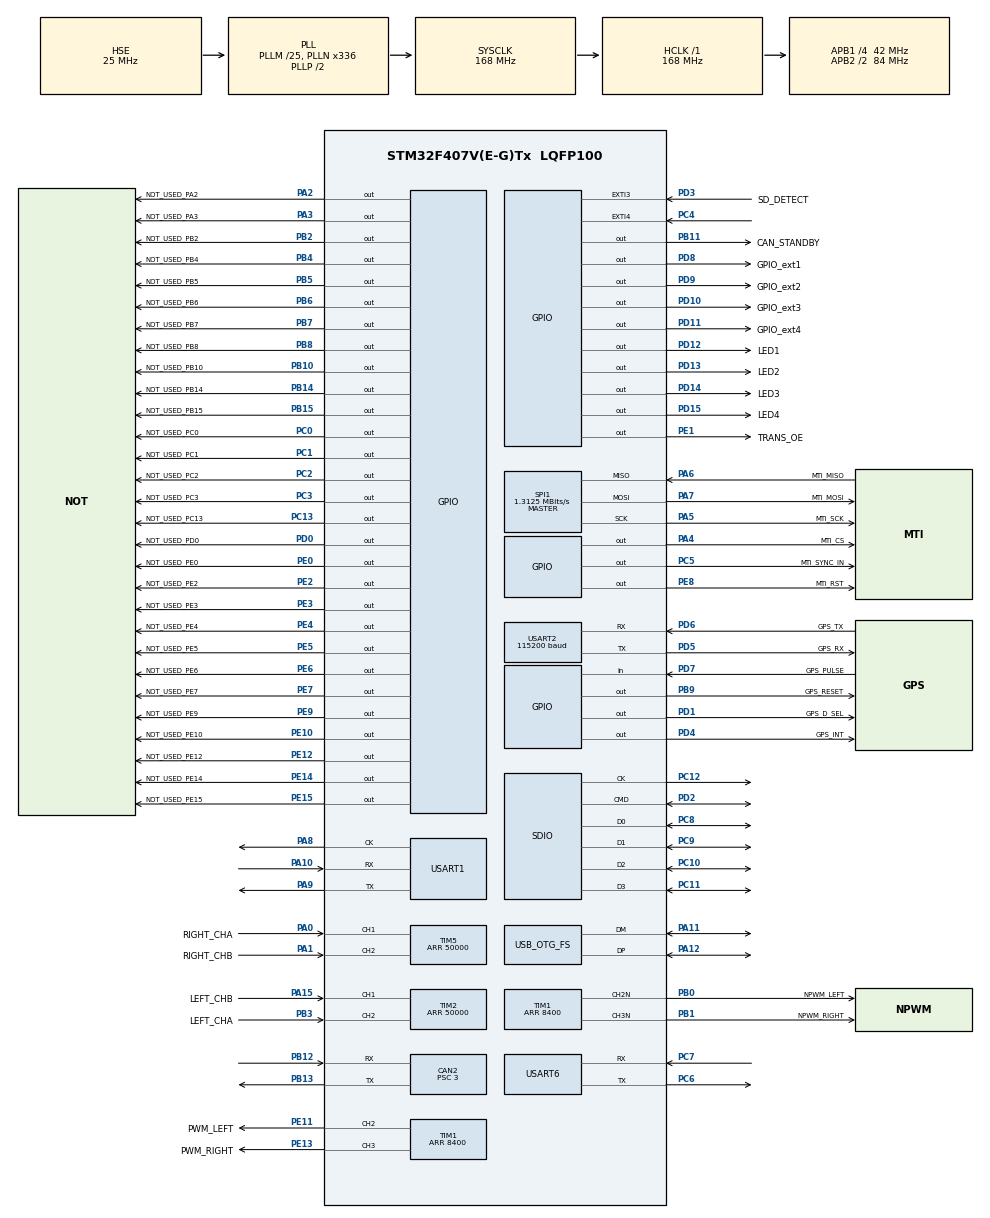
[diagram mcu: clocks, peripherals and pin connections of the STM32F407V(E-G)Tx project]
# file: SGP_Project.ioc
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CAN2.BS1=CAN_BS1_13TQ
CAN2.BS2=CAN_BS2_2TQ
CAN2.CalculateTimeBit=1142
CAN2.CalculateTimeQuantum=71.42857142857143
CAN2.Prescaler=3
Mcu.Family=STM32F4
Mcu.Name=STM32F407V(E-G)Tx
Mcu.Package=LQFP100
NVIC.CAN2_RX0_IRQn=true\:1\:0\:true\:true\:true\:5\:true
NVIC.CAN2_RX1_IRQn=true\:1\:0\:true\:true\:true\:6\:true
NVIC.CAN2_TX_IRQn=true\:0\:0\:false\:false\:true\:true
NVIC.EXTI3_IRQn=true\:1\:0\:true\:true\:true\:1\:true
NVIC.EXTI4_IRQn=true\:0\:0\:false\:true\:true\:10\:true
NVIC.OTG_FS_IRQn=true\:1\:0\:true\:true\:true\:7\:true
NVIC.PriorityGroup=NVIC_PRIORITYGROUP_4
NVIC.TIM3_IRQn=true\:3\:0\:true\:true\:true\:2\:true
NVIC.TIM4_IRQn=true\:4\:0\:true\:true\:true\:3\:true
NVIC.TIM6_DAC_IRQn=true\:2\:0\:true\:true\:true\:4\:true
NVIC.USART2_IRQn=true\:1\:0\:true\:true\:true\:8\:true
NVIC.USART6_IRQn=true\:1\:0\:true\:true\:true\:9\:true
PA0-WKUP.GPIO_Label=RIGHT_CHA
PA0-WKUP.Signal=S_TIM5_CH1
PA1.GPIO_Label=RIGHT_CHB
PA1.Signal=S_TIM5_CH2
PA10.GPIO_Speed=GPIO_SPEED_FREQ_MEDIUM
PA10.Mode=Synchronous
PA10.Signal=USART1_RX
PA11.GPIO_Speed=GPIO_SPEED_FREQ_HIGH
PA11.Mode=Device_Only
PA11.Signal=USB_OTG_FS_DM
PA12.GPIO_Speed=GPIO_SPEED_FREQ_HIGH
PA12.Mode=Device_Only
PA12.Signal=USB_OTG_FS_DP
PA13.Mode=Serial_Wire
PA13.Signal=SYS_JTMS-SWDIO
PA14.Mode=Serial_Wire
PA14.Signal=SYS_JTCK-SWCLK
PA15.GPIO_Label=LEFT_CHB
PA15.Signal=S_TIM2_CH1_ETR
PA2.GPIO_Label=NOT_USED_PA2
PA2.GPIO_PuPd=GPIO_PULLDOWN
PA2.Signal=GPIO_Output
PA3.GPIO_Label=NOT_USED_PA3
PA3.GPIO_PuPd=GPIO_PULLDOWN
PA3.Signal=GPIO_Output
PA4.GPIO_Label=MTi_CS
PA4.GPIO_PuPd=GPIO_PULLDOWN
PA4.Signal=GPIO_Output
PA5.GPIO_Label=MTi_SCK
PA5.Mode=Full_Duplex_Master
PA5.Signal=SPI1_SCK
PA6.GPIO_Label=MTi_MISO
PA6.Mode=Full_Duplex_Master
PA6.Signal=SPI1_MISO
PA7.GPIO_Label=MTi_MOSI
PA7.Mode=Full_Duplex_Master
PA7.Signal=SPI1_MOSI
PA8.GPIO_Speed=GPIO_SPEED_FREQ_MEDIUM
PA8.Mode=Synchronous
PA8.Signal=USART1_CK
PA9.GPIO_Speed=GPIO_SPEED_FREQ_MEDIUM
PA9.Mode=Synchronous
PA9.Signal=USART1_TX
PB0.GPIO_Label=NPWM_LEFT
PB0.Mode=PWM Generation2 CH2 CH2N
PB0.Signal=TIM1_CH2N
PB1.GPIO_Label=NPWM_RIGHT
PB1.Mode=PWM Generation3 CH3 CH3N
PB1.Signal=TIM1_CH3N
PB10.GPIO_Label=NOT_USED_PB10
PB10.GPIO_PuPd=GPIO_PULLDOWN
PB10.Signal=GPIO_Output
PB11.GPIO_Label=CAN_STANDBY
PB11.GPIO_PuPd=GPIO_PULLDOWN
PB11.Signal=GPIO_Output
PB12.GPIO_PuPd=GPIO_PULLUP
PB12.GPIO_Speed=GPIO_SPEED_FREQ_VERY_HIGH
PB12.Mode=Slave
PB12.Signal=CAN2_RX
PB13.GPIO_PuPd=GPIO_PULLUP
PB13.GPIO_Speed=GPIO_SPEED_FREQ_VERY_HIGH
PB13.Mode=Slave
PB13.Signal=CAN2_TX
PB14.GPIO_Label=NOT_USED_PB14
PB14.GPIO_PuPd=GPIO_PULLDOWN
PB14.Signal=GPIO_Output
PB15.GPIO_Label=NOT_USED_PB15
PB15.GPIO_PuPd=GPIO_PULLDOWN
PB15.Signal=GPIO_Output
PB2.GPIO_Label=NOT_USED_PB2
PB2.GPIO_PuPd=GPIO_PULLDOWN
PB2.Signal=GPIO_Output
PB3.GPIO_Label=LEFT_CHA
PB3.Signal=S_TIM2_CH2
PB4.GPIO_Label=NOT_USED_PB4
PB4.GPIO_PuPd=GPIO_PULLDOWN
PB4.Signal=GPIO_Output
PB5.GPIO_Label=NOT_USED_PB5
PB5.GPIO_PuPd=GPIO_PULLDOWN
PB5.Signal=GPIO_Output
PB6.GPIO_Label=NOT_USED_PB6
PB6.GPIO_PuPd=GPIO_PULLDOWN
PB6.Signal=GPIO_Output
PB7.GPIO_Label=NOT_USED_PB7
PB7.GPIO_PuPd=GPIO_PULLDOWN
PB7.Signal=GPIO_Output
PB8.GPIO_Label=NOT_USED_PB8
PB8.GPIO_PuPd=GPIO_PULLDOWN
PB8.Signal=GPIO_Output
PB9.GPIO_Label=GPS_RESET
PB9.GPIO_PuPd=GPIO_PULLDOWN
PB9.Signal=GPIO_Output
PC0.GPIO_Label=NOT_USED_PC0
PC0.GPIO_PuPd=GPIO_PULLDOWN
PC0.Signal=GPIO_Output
PC1.GPIO_Label=NOT_USED_PC1
PC1.GPIO_PuPd=GPIO_PULLDOWN
PC1.Signal=GPIO_Output
PC10.GPIO_PuPd=GPIO_PULLUP
PC10.Mode=SD_4_bits_Wide_bus
PC10.Signal=SDIO_D2
PC11.GPIO_PuPd=GPIO_PULLUP
PC11.Mode=SD_4_bits_Wide_bus
PC11.Signal=SDIO_D3
PC12.GPIO_PuPd=GPIO_PULLUP
PC12.Mode=SD_4_bits_Wide_bus
PC12.Signal=SDIO_CK
PC13-ANTI_TAMP.GPIO_Label=NOT_USED_PC13
PC13-ANTI_TAMP.GPIO_PuPd=GPIO_PULLDOWN
PC13-ANTI_TAMP.Signal=GPIO_Output
PC14-OSC32_IN.Mode=LSE-External-Oscillator
PC14-OSC32_IN.Signal=RCC_OSC32_IN
PC15-OSC32_OUT.Mode=LSE-External-Oscillator
PC15-OSC32_OUT.Signal=RCC_OSC32_OUT
PC2.GPIO_Label=NOT_USED_PC2
PC2.GPIO_PuPd=GPIO_PULLDOWN
PC2.Signal=GPIO_Output
PC3.GPIO_Label=NOT_USED_PC3
PC3.GPIO_PuPd=GPIO_PULLDOWN
PC3.Signal=GPIO_Output
PC4.Signal=GPXTI4
PC5.GPIO_Label=MTi_SYNC_IN
PC5.GPIO_PuPd=GPIO_PULLDOWN
PC5.Signal=GPIO_Output
PC6.GPIO_Speed=GPIO_SPEED_FREQ_MEDIUM
PC6.Mode=Asynchronous
PC6.Signal=USART6_TX
PC7.GPIO_Speed=GPIO_SPEED_FREQ_MEDIUM
PC7.Mode=Asynchronous
PC7.Signal=USART6_RX
PC8.GPIO_PuPd=GPIO_PULLUP
PC8.Mode=SD_4_bits_Wide_bus
PC8.Signal=SDIO_D0
PC9.GPIO_PuPd=GPIO_PULLUP
PC9.Mode=SD_4_bits_Wide_bus
PC9.Signal=SDIO_D1
PD0.GPIO_Label=NOT_USED_PD0
PD0.GPIO_PuPd=GPIO_PULLDOWN
PD0.Signal=GPIO_Output
PD1.GPIO_Label=GPS_D_SEL
PD1.GPIO_PuPd=GPIO_PULLDOWN
PD1.Signal=GPIO_Output
PD10.GPIO_Label=GPIO_ext3
PD10.GPIO_PuPd=GPIO_PULLDOWN
PD10.Signal=GPIO_Output
PD11.GPIO_Label=GPIO_ext4
PD11.GPIO_PuPd=GPIO_PULLDOWN
PD11.Signal=GPIO_Output
PD12.GPIO_Label=LED1
PD12.GPIO_PuPd=GPIO_PULLDOWN
PD12.Signal=GPIO_Output
PD13.GPIO_Label=LED2
PD13.GPIO_PuPd=GPIO_PULLDOWN
PD13.Signal=GPIO_Output
PD14.GPIO_Label=LED3
PD14.GPIO_PuPd=GPIO_PULLDOWN
PD14.Signal=GPIO_Output
PD15.GPIO_Label=LED4
PD15.GPIO_PuPd=GPIO_PULLDOWN
PD15.Signal=GPIO_Output
PD2.GPIO_PuPd=GPIO_PULLUP
PD2.Mode=SD_4_bits_Wide_bus
PD2.Signal=SDIO_CMD
PD3.GPIO_Label=SD_DETECT
PD3.GPIO_ModeDefaultEXTI=GPIO_MODE_IT_RISING_FALLING
PD3.GPIO_PuPd=GPIO_PULLDOWN
PD3.Signal=GPXTI3
PD4.GPIO_Label=GPS_INT
PD4.GPIO_PuPd=GPIO_PULLDOWN
PD4.Signal=GPIO_Output
PD5.GPIO_Label=GPS_RX
PD5.GPIO_Speed=GPIO_SPEED_FREQ_MEDIUM
PD5.Mode=Asynchronous
PD5.Signal=USART2_TX
PD6.GPIO_Label=GPS_TX
PD6.GPIO_Speed=GPIO_SPEED_FREQ_MEDIUM
PD6.Mode=Asynchronous
PD6.Signal=USART2_RX
PD7.GPIO_Label=GPS_PULSE
PD7.GPIO_PuPd=GPIO_PULLDOWN
PD7.Signal=GPIO_Input
PD8.GPIO_Label=GPIO_ext1
PD8.GPIO_PuPd=GPIO_PULLDOWN
PD8.Signal=GPIO_Output
PD9.GPIO_Label=GPIO_ext2
PD9.GPIO_PuPd=GPIO_PULLDOWN
PD9.Signal=GPIO_Output
PE0.GPIO_Label=NOT_USED_PE0
PE0.GPIO_PuPd=GPIO_PULLDOWN
PE0.Signal=GPIO_Output
PE1.GPIO_Label=TRANS_OE
PE1.GPIO_PuPd=GPIO_PULLDOWN
PE1.Signal=GPIO_Output
PE10.GPIO_Label=NOT_USED_PE10
PE10.GPIO_PuPd=GPIO_PULLDOWN
PE10.Signal=GPIO_Output
PE11.GPIO_Label=PWM_LEFT
PE11.Signal=S_TIM1_CH2
PE12.GPIO_Label=NOT_USED_PE12
PE12.GPIO_PuPd=GPIO_PULLDOWN
PE12.Signal=GPIO_Output
PE13.GPIO_Label=PWM_RIGHT
PE13.Signal=S_TIM1_CH3
PE14.GPIO_Label=NOT_USED_PE14
PE14.GPIO_PuPd=GPIO_PULLDOWN
PE14.Signal=GPIO_Output
PE15.GPIO_Label=NOT_USED_PE15
PE15.GPIO_PuPd=GPIO_PULLDOWN
PE15.Signal=GPIO_Output
PE2.GPIO_Label=NOT_USED_PE2
PE2.GPIO_PuPd=GPIO_PULLDOWN
PE2.Signal=GPIO_Output
PE3.GPIO_Label=NOT_USED_PE3
PE3.GPIO_PuPd=GPIO_PULLDOWN
PE3.Signal=GPIO_Output
PE4.GPIO_Label=NOT_USED_PE4
PE4.GPIO_PuPd=GPIO_PULLDOWN
PE4.Signal=GPIO_Output
PE5.GPIO_Label=NOT_USED_PE5
PE5.GPIO_PuPd=GPIO_PULLDOWN
PE5.Signal=GPIO_Output
PE6.GPIO_Label=NOT_USED_PE6
PE6.GPIO_PuPd=GPIO_PULLDOWN
PE6.Signal=GPIO_Output
PE7.GPIO_Label=NOT_USED_PE7
PE7.GPIO_PuPd=GPIO_PULLDOWN
PE7.Signal=GPIO_Output
PE8.GPIO_Label=MTi_RST
PE8.GPIO_PuPd=GPIO_PULLDOWN
PE8.Signal=GPIO_Output
PE9.GPIO_Label=NOT_USED_PE9
PE9.GPIO_PuPd=GPIO_PULLDOWN
PE9.Signal=GPIO_Output
PH0-OSC_IN.Mode=HSE-External-Clock-Source
PH0-OSC_IN.Signal=RCC_OSC_IN
PH1-OSC_OUT.Mode=HSE-External-Clock-Source
PH1-OSC_OUT.Signal=RCC_OSC_OUT
ProjectManager.HeapSize=0x200
ProjectManager.StackSize=0x400
ProjectManager.TargetToolchain=TrueSTUDIO
RCC.48MHZClocksFreq_Value=48000000
RCC.AHBCLKDivider=RCC_SYSCLK_DIV1
RCC.AHBFreq_Value=168000000
RCC.APB1CLKDivider=RCC_HCLK_DIV4
RCC.APB1Freq_Value=42000000
RCC.APB1TimFreq_Value=84000000
RCC.APB2CLKDivider=RCC_HCLK_DIV2
RCC.APB2Freq_Value=84000000
RCC.APB2TimFreq_Value=168000000
RCC.CortexFreq_Value=168000000
RCC.Cortex_Div=SYSTICK_CLKSOURCE_HCLK
RCC.HCLKFreq_Value=168000000
RCC.HSE_VALUE=25000000
RCC.HSI_VALUE=16000000
RCC.OscillatorTypeHSI=RCC_OSCILLATORTYPE_HSI
RCC.PLLM=25
RCC.PLLN=336
RCC.PLLP=RCC_PLLP_DIV2
RCC.PLLQ=7
RCC.RCC_MCODiv1=RCC_MCODIV_1
RCC.RCC_MCODiv2=RCC_MCODIV_1
RCC.RCC_RTC_Clock_Source=RCC_RTCCLKSOURCE_LSE
RCC.RCC_RTC_Clock_SourceVirtual=RCC_RTCCLKSOURCE_LSE
RCC.RCC_RTC_Clock_Source_FROM_HSE=RCC_RTCCLKSOURCE_HSE_DIV2
RCC.SYSCLKFreq_VALUE=168000000
RCC.SYSCLKSource=RCC_SYSCLKSOURCE_PLLCLK
RCC.VCOOutputFreq_Value=336000000
RTC.Alarm=RTC_ALARM_A
SH.S_TIM1_CH2.0=TIM1_CH2,PWM Generation2 CH2 CH2N
SH.S_TIM1_CH3.0=TIM1_CH3,PWM Generation3 CH3 CH3N
SH.S_TIM2_CH1_ETR.0=TIM2_CH1,Encoder_Interface
SH.S_TIM2_CH2.0=TIM2_CH2,Encoder_Interface
SH.S_TIM5_CH1.0=TIM5_CH1,Encoder_Interface
SH.S_TIM5_CH2.0=TIM5_CH2,Encoder_Interface
SPI1.BaudRatePrescaler=SPI_BAUDRATEPRESCALER_64
SPI1.CLKPhase=SPI_PHASE_2EDGE
SPI1.CLKPolarity=SPI_POLARITY_HIGH
SPI1.CalculateBaudRate=1.3125 MBits/s
SPI1.Direction=SPI_DIRECTION_2LINES
SPI1.Mode=SPI_MODE_MASTER
SPI1.VirtualType=VM_MASTER
TIM1.Channel-PWM\ Generation2\ CH2\ CH2N=TIM_CHANNEL_2
TIM1.Channel-PWM\ Generation3\ CH3\ CH3N=TIM_CHANNEL_3
TIM1.Period=8400
TIM2.Period=50000
TIM3.Period=21000
TIM3.Prescaler=200
TIM4.Period=42000
TIM4.Prescaler=2000
TIM5.Period=50000
TIM6.Period=42000
TIM6.Prescaler=10000
USART1.VirtualMode=VM_SYNC
USART2.BaudRate=115200
USART2.VirtualMode=VM_ASYNC
USART6.VirtualMode=VM_ASYNC
USB_DEVICE.CLASS_NAME_FS=CDC
USB_DEVICE.VirtualModeFS=Cdc_FS
USB_OTG_FS.VirtualMode=Device_Only
VP_FATFS_VS_SDIO.Mode=SDIO
VP_RTC_VS_RTC_Activate.Mode=RTC_Enabled
VP_RTC_VS_RTC_Alarm_A_Intern.Mode=Alarm A
VP_RTC_VS_RTC_Calendar.Mode=RTC_Calendar
VP_TIM1_VS_ClockSourceINT.Mode=Internal
VP_TIM3_VS_ClockSourceINT.Mode=Internal
VP_TIM3_VS_ClockSourceITR.Mode=TriggerSource_ITR0
VP_TIM4_VS_ClockSourceINT.Mode=Internal
VP_TIM4_VS_ClockSourceITR.Mode=TriggerSource_ITR0
VP_TIM6_VS_ClockSourceINT.Mode=Enable_Timer
VP_USB_DEVICE_VS_USB_DEVICE_CDC_FS.Mode=CDC_FS
board=SGP_Project

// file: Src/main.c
/**
  ******************************************************************************
  * File Name          : main.c
  * Description        : Main program body
  ******************************************************************************
  *
  * Copyright (c) 2018 STMicroelectronics International N.V.
  * All rights reserved.
  *
  * Redistribution and use in source and binary forms, with or without
  * modification, are permitted, provided that the following conditions are met:
  *
  * 1. Redistribution of source code must retain the above copyright notice,
  *    this list of conditions and the following disclaimer.
  * 2. Redistributions in binary form must reproduce the above copyright notice,
  *    this list of conditions and the following disclaimer in the documentation
  *    and/or other materials provided with the distribution.
  * 3. Neither the name of STMicroelectronics nor the names of other
  *    contributors to this software may be used to endorse or promote products
  *    derived from this software without specific written permission.
  * 4. This software, including modifications and/or derivative works of this
  *    software, must execute solely and exclusively on microcontroller or
  *    microprocessor devices manufactured by or for STMicroelectronics.
  * 5. Redistribution and use of this software other than as permitted under
  *    this license is void and will automatically terminate your rights under
  *    this license.
  *
  * THIS SOFTWARE IS PROVIDED BY STMICROELECTRONICS AND CONTRIBUTORS "AS IS"
  * AND ANY EXPRESS, IMPLIED OR STATUTORY WARRANTIES, INCLUDING, BUT NOT
  * LIMITED TO, THE IMPLIED WARRANTIES OF MERCHANTABILITY, FITNESS FOR A
  * PARTICULAR PURPOSE AND NON-INFRINGEMENT OF THIRD PARTY INTELLECTUAL PROPERTY
  * RIGHTS ARE DISCLAIMED TO THE FULLEST EXTENT PERMITTED BY LAW. IN NO EVENT
  * SHALL STMICROELECTRONICS OR CONTRIBUTORS BE LIABLE FOR ANY DIRECT, INDIRECT,
  * INCIDENTAL, SPECIAL, EXEMPLARY, OR CONSEQUENTIAL DAMAGES (INCLUDING, BUT NOT
  * LIMITED TO, PROCUREMENT OF SUBSTITUTE GOODS OR SERVICES; LOSS OF USE, DATA,
  * OR PROFITS; OR BUSINESS INTERRUPTION) HOWEVER CAUSED AND ON ANY THEORY OF
  * LIABILITY, WHETHER IN CONTRACT, STRICT LIABILITY, OR TORT (INCLUDING
  * NEGLIGENCE OR OTHERWISE) ARISING IN ANY WAY OUT OF THE USE OF THIS SOFTWARE,
  * EVEN IF ADVISED OF THE POSSIBILITY OF SUCH DAMAGE.
  *
  ******************************************************************************
  */
#include "main.h"
#include "stm32f4xx_hal.h"
#include "can.h"
#include "fatfs.h"
#include "rtc.h"
#include "sdio.h"
#include "spi.h"
#include "tim.h"
#include "usart.h"
#include "usb_device.h"
#include "gpio.h"

/* USER CODE BEGIN Includes */
#include "string.h"
#include "stdlib.h"
#include "usb_device.h"
#include "usbd_core.h"
#include "usbd_desc.h"
#include "usbd_cdc.h"
#include "usbd_cdc_if.h"

#include "SGP_Control.h"
#include "motorcmd.h"
#include "SD_save.h"
#include "GPS.h"
#include "serial_com.h"
#include "mti.h"
/* USER CODE END Includes */

/* USER CODE BEGIN PV */
/* Private variables ---------------------------------------------------------*/

//temp
uint8_t temp_val = 0;
// buffer pour comm CANbus
CanTxMsgTypeDef CanTx_msg;
CanRxMsgTypeDef CanRx_msg;
CAN_FilterConfTypeDef CAN_FilterStruct;

extern FATFS fs;         // Work area (file system object) for logical drive
extern FIL data_file;  // file objects for data logging
extern FIL error_file;  // file objects for error logging
//FRESULT res;        // FatFs function common result code
extern uint32_t byteread, bytewritten;         // File R/W count

/* USER CODE END PV */

void SystemClock_Config(void);
void Error_Handler(void);
static void MX_NVIC_Init(void);

/* USER CODE BEGIN PFP */
/* Private function prototypes -----------------------------------------------*/

/* USER CODE END PFP */

/* USER CODE BEGIN 0 */
HAL_StatusTypeDef result;
/* USER CODE END 0 */

int main(void)
{

  /* MCU Configuration----------------------------------------------------------*/

  /* Reset of all peripherals, Initializes the Flash interface and the Systick. */
  HAL_Init();

  /* Configure the system clock */
  SystemClock_Config();

  /* Initialize all configured peripherals */
  MX_GPIO_Init();
  MX_CAN2_Init();
  MX_RTC_Init();
  MX_SDIO_SD_Init();
  MX_SPI1_Init();
  MX_TIM1_Init();
  MX_TIM2_Init();
  MX_TIM3_Init();
  MX_TIM5_Init();
  MX_USART1_Init();
  MX_USART2_UART_Init();
  MX_FATFS_Init();
  MX_USB_DEVICE_Init();
  MX_TIM4_Init();
  MX_TIM6_Init();
  MX_USART6_UART_Init();

  /* Initialize interrupts */
  MX_NVIC_Init();

  /* USER CODE BEGIN 2 */

	hcan2.pTxMsg = &CanTx_msg;
	hcan2.pRxMsg = &CanRx_msg;

	CAN_FilterStruct.FilterNumber = 14; //Specifies the filter which will be initialized.
	CAN_FilterStruct.FilterMode = CAN_FILTERMODE_IDMASK; //Specifies the filter mode to be initialized.
														 //CAN_FILTERMODE_IDLIST : Identifier list mode
	CAN_FilterStruct.FilterScale = CAN_FILTERSCALE_32BIT;
	CAN_FilterStruct.FilterIdHigh = 0; //Specifies the filter identification number (MSBs for a 32-bit configuration, first one for a 16-bit configuration).
	CAN_FilterStruct.FilterIdLow = 0;
	CAN_FilterStruct.FilterMaskIdHigh = 0;
	CAN_FilterStruct.FilterMaskIdLow = 0;
	CAN_FilterStruct.FilterFIFOAssignment = CAN_FILTER_FIFO0;
	CAN_FilterStruct.FilterActivation = ENABLE; /* Enable this filter */
	CAN_FilterStruct.BankNumber = 14;

	HAL_CAN_ConfigFilter(&hcan2, &CAN_FilterStruct);

	hcan2.pTxMsg->StdId = 0x244;
	hcan2.pTxMsg->RTR = CAN_RTR_DATA;
	hcan2.pTxMsg->IDE = CAN_ID_STD;
	hcan2.pTxMsg->DLC = 1;

	//init main handlers and stuff
	//SD_Save_Init();
	//Motor_Init();
	GPS_Init();
	//SGP_Control_Init();

	//MTi release reset
	HAL_GPIO_WritePin(MTi_RST_GPIO_Port, MTi_RST_Pin, GPIO_PIN_RESET);

	HAL_Delay(1000);

	//start uart interrupt for GPS, cte lenght rx

	//TIMER START
	//HAL_TIM_Base_Start(&htim2);
	HAL_TIM_Base_Start_IT(&htim3);
	//HAL_TIM_Base_Start_IT(&htim4);
	//HAL_TIM_Base_Start_IT(&htim6);

	//MTi release reset
	HAL_GPIO_WritePin(MTi_RST_GPIO_Port, MTi_RST_Pin, GPIO_PIN_SET);

	//CAN START
	HAL_GPIO_WritePin(CAN_STANDBY_GPIO_Port, CAN_STANDBY_Pin, GPIO_PIN_RESET);
	__HAL_CAN_ENABLE_IT(&hcan2, CAN_IT_FMP0);

  /* USER CODE END 2 */

  /* Infinite loop */
  /* USER CODE BEGIN WHILE */
	while (1) {
		HAL_Delay(250);
		HAL_GPIO_TogglePin(LED1_GPIO_Port, LED1_Pin);
  /* USER CODE END WHILE */

	}

}

/** System Clock Configuration
*/
void SystemClock_Config(void)
{

  RCC_OscInitTypeDef RCC_OscInitStruct;
  RCC_ClkInitTypeDef RCC_ClkInitStruct;
  RCC_PeriphCLKInitTypeDef PeriphClkInitStruct;

    /**Configure the main internal regulator output voltage
    */
  __HAL_RCC_PWR_CLK_ENABLE();

  __HAL_PWR_VOLTAGESCALING_CONFIG(PWR_REGULATOR_VOLTAGE_SCALE1);

    /**Initializes the CPU, AHB and APB busses clocks
    */
  RCC_OscInitStruct.OscillatorType = RCC_OSCILLATORTYPE_LSE|RCC_OSCILLATORTYPE_HSE;
  RCC_OscInitStruct.HSEState = RCC_HSE_BYPASS;
  RCC_OscInitStruct.LSEState = RCC_LSE_ON;
  RCC_OscInitStruct.PLL.PLLState = RCC_PLL_ON;
  RCC_OscInitStruct.PLL.PLLSource = RCC_PLLSOURCE_HSE;
  RCC_OscInitStruct.PLL.PLLM = 25;
  RCC_OscInitStruct.PLL.PLLN = 336;
  RCC_OscInitStruct.PLL.PLLP = RCC_PLLP_DIV2;
  RCC_OscInitStruct.PLL.PLLQ = 7;
  if (HAL_RCC_OscConfig(&RCC_OscInitStruct) != HAL_OK)
  {
    Error_Handler();
  }

    /**Initializes the CPU, AHB and APB busses clocks
    */
  RCC_ClkInitStruct.ClockType = RCC_CLOCKTYPE_HCLK|RCC_CLOCKTYPE_SYSCLK
                              |RCC_CLOCKTYPE_PCLK1|RCC_CLOCKTYPE_PCLK2;
  RCC_ClkInitStruct.SYSCLKSource = RCC_SYSCLKSOURCE_PLLCLK;
  RCC_ClkInitStruct.AHBCLKDivider = RCC_SYSCLK_DIV1;
  RCC_ClkInitStruct.APB1CLKDivider = RCC_HCLK_DIV4;
  RCC_ClkInitStruct.APB2CLKDivider = RCC_HCLK_DIV2;

  if (HAL_RCC_ClockConfig(&RCC_ClkInitStruct, FLASH_LATENCY_5) != HAL_OK)
  {
    Error_Handler();
  }

  PeriphClkInitStruct.PeriphClockSelection = RCC_PERIPHCLK_RTC;
  PeriphClkInitStruct.RTCClockSelection = RCC_RTCCLKSOURCE_LSE;
  if (HAL_RCCEx_PeriphCLKConfig(&PeriphClkInitStruct) != HAL_OK)
  {
    Error_Handler();
  }

    /**Configure the Systick interrupt time
    */
  HAL_SYSTICK_Config(HAL_RCC_GetHCLKFreq()/1000);

    /**Configure the Systick
    */
  HAL_SYSTICK_CLKSourceConfig(SYSTICK_CLKSOURCE_HCLK);

  /* SysTick_IRQn interrupt configuration */
  HAL_NVIC_SetPriority(SysTick_IRQn, 0, 0);
}

/** NVIC Configuration
*/
static void MX_NVIC_Init(void)
{
  /* EXTI3_IRQn interrupt configuration */
  HAL_NVIC_SetPriority(EXTI3_IRQn, 1, 0);
  HAL_NVIC_EnableIRQ(EXTI3_IRQn);
  /* TIM3_IRQn interrupt configuration */
  HAL_NVIC_SetPriority(TIM3_IRQn, 3, 0);
  HAL_NVIC_EnableIRQ(TIM3_IRQn);
  /* TIM4_IRQn interrupt configuration */
  HAL_NVIC_SetPriority(TIM4_IRQn, 4, 0);
  HAL_NVIC_EnableIRQ(TIM4_IRQn);
  /* TIM6_DAC_IRQn interrupt configuration */
  HAL_NVIC_SetPriority(TIM6_DAC_IRQn, 2, 0);
  HAL_NVIC_EnableIRQ(TIM6_DAC_IRQn);
  /* CAN2_RX0_IRQn interrupt configuration */
  HAL_NVIC_SetPriority(CAN2_RX0_IRQn, 1, 0);
  HAL_NVIC_EnableIRQ(CAN2_RX0_IRQn);
  /* CAN2_RX1_IRQn interrupt configuration */
  HAL_NVIC_SetPriority(CAN2_RX1_IRQn, 1, 0);
  HAL_NVIC_EnableIRQ(CAN2_RX1_IRQn);
  /* OTG_FS_IRQn interrupt configuration */
  HAL_NVIC_SetPriority(OTG_FS_IRQn, 1, 0);
  HAL_NVIC_EnableIRQ(OTG_FS_IRQn);
  /* USART2_IRQn interrupt configuration */
  HAL_NVIC_SetPriority(USART2_IRQn, 1, 0);
  HAL_NVIC_EnableIRQ(USART2_IRQn);
  /* USART6_IRQn interrupt configuration */
  HAL_NVIC_SetPriority(USART6_IRQn, 1, 0);
  HAL_NVIC_EnableIRQ(USART6_IRQn);
  /* EXTI4_IRQn interrupt configuration */
  HAL_NVIC_SetPriority(EXTI4_IRQn, 2, 0);
  HAL_NVIC_EnableIRQ(EXTI4_IRQn);
}

/* USER CODE BEGIN 4 */

/* All peripheral callback are here */
//TIMER
void HAL_TIM_PeriodElapsedCallback(TIM_HandleTypeDef *htim) {

	static int tim3Counter = 1;

	if (htim->Instance == TIM3) {
		if (!(tim3Counter % 20)) {
			GPS_Read_Data();
		}

        tim3Counter++;
        if (tim3Counter > 20) {
            tim3Counter = 1;
        }
	}
}

/* peripheral callback END */

/* USER CODE END 4 */

void Error_Handler(void)
{
	while (1) {
	}
}

/************************ (C) COPYRIGHT STMicroelectronics *****END OF FILE****/
